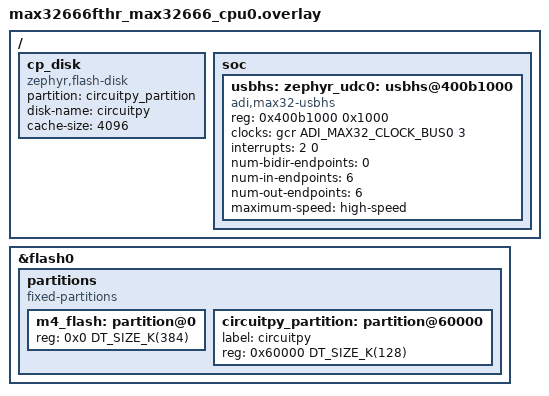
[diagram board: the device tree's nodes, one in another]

/ {
    cp_disk {
        compatible = "zephyr,flash-disk";
        partition = <&circuitpy_partition>;
        disk-name = "circuitpy";
        cache-size = <4096>;
    };

    /* TODO: Add to MAX32666 soc dts */
    soc {
        usbhs: usbhs@400b1000 {
            compatible = "adi,max32-usbhs";
            reg = <0x400b1000 0x1000>;
            clocks = <&gcr ADI_MAX32_CLOCK_BUS0 3>;
            interrupts = <2 0>;
            num-bidir-endpoints = <0>;
            num-in-endpoints = <6>;
            num-out-endpoints = <6>;
            maximum-speed = "high-speed";
            status = "disabled";
        };
    };
};

&flash0 {
    partitions {
        compatible = "fixed-partitions";
        #address-cells = <1>;
        #size-cells = <1>;

        m4_flash: partition@0 {
            reg = <0x0 DT_SIZE_K(384)>;
        };

        circuitpy_partition: partition@60000 {
            label = "circuitpy";
            reg = <0x60000 DT_SIZE_K(128)>;
        };
    };
};

/* TODO: Add to MAX32666FTHR board dts */
zephyr_udc0: &usbhs {
    status = "okay";
};

#include "../app.overlay"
